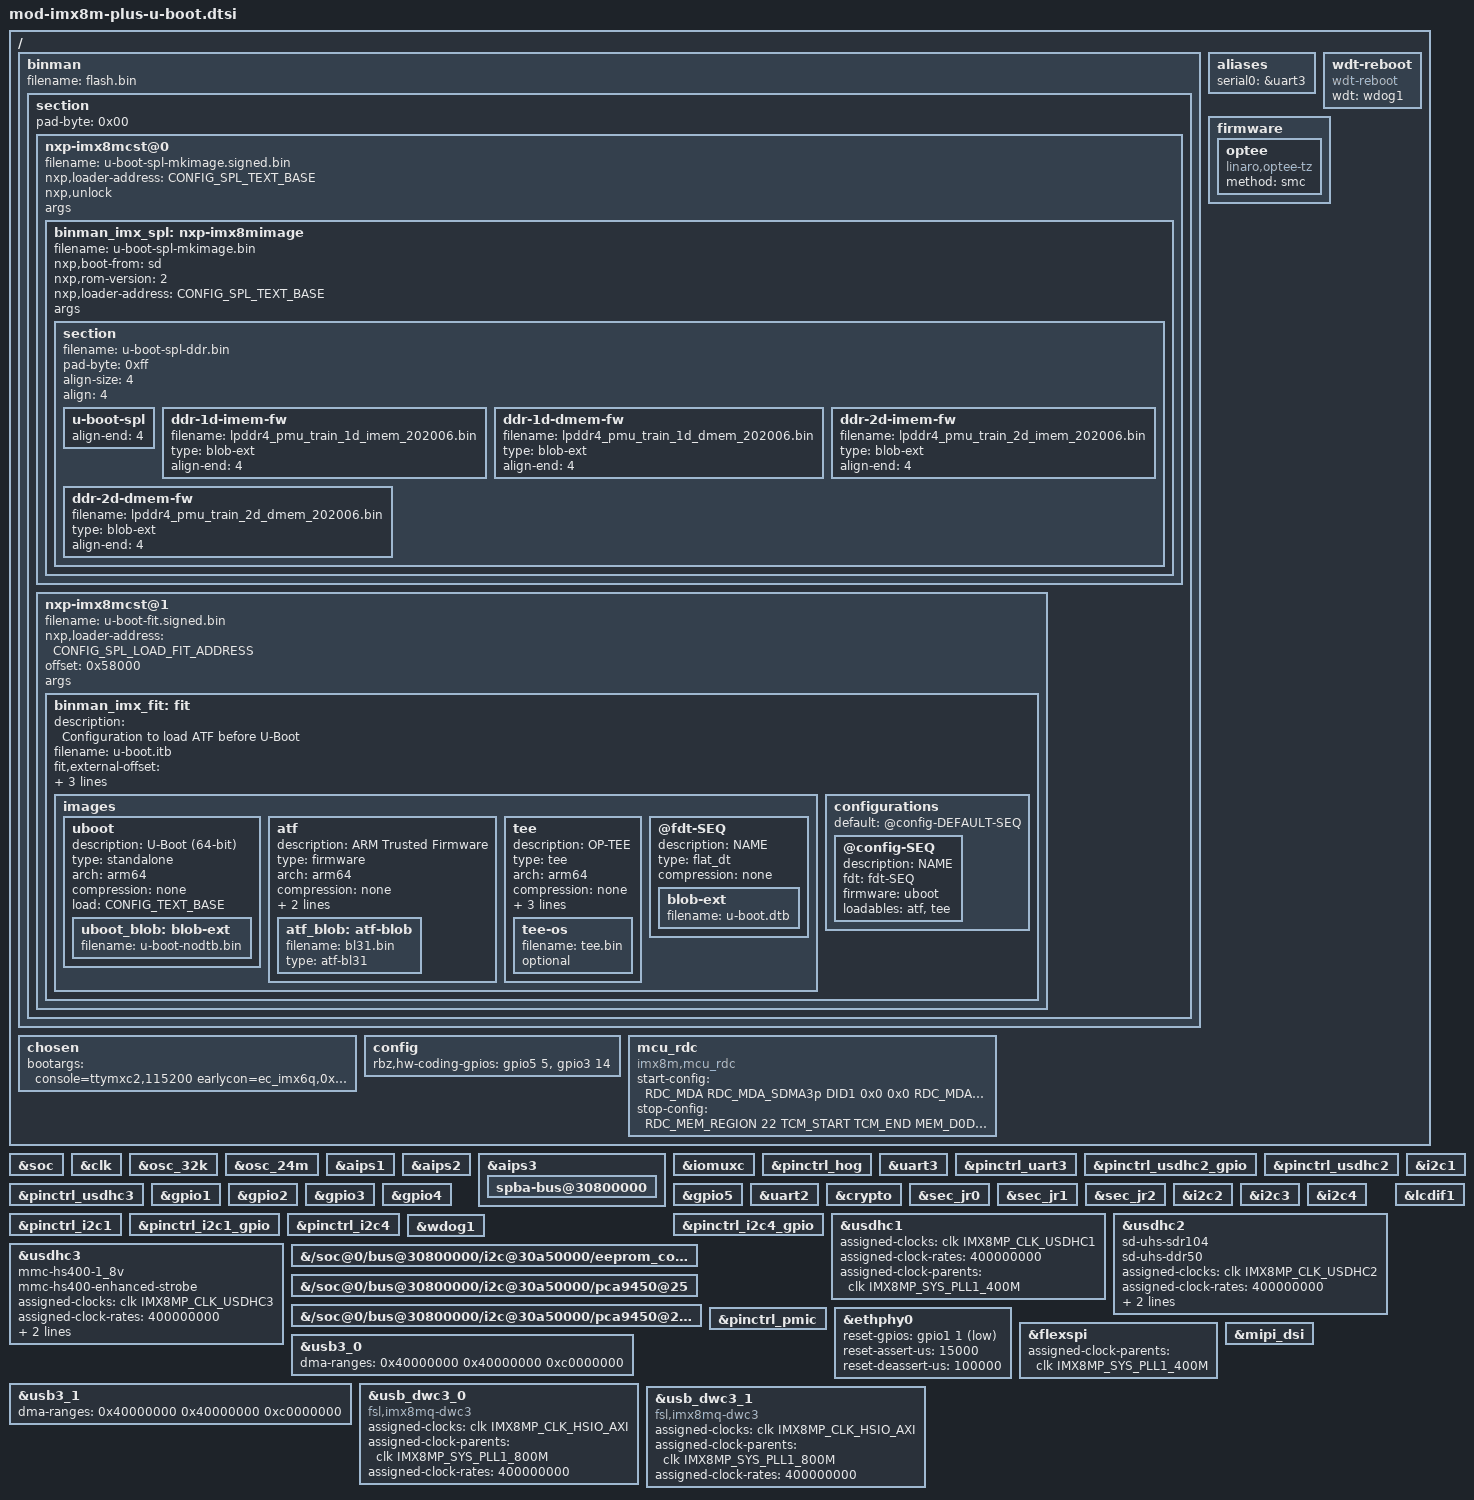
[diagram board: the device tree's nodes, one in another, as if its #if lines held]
// SPDX-License-Identifier: GPL-2.0+
/*
 * Copyright 2019 NXP
 */
#include "imx8mp-sec-def.h"

/ {
	binman: binman {
	};

    aliases {
      serial0 = &uart3;
    };

	chosen {
		bootargs = "console=ttymxc2,115200 earlycon=ec_imx6q,0x30880000,115200";
	};

    config {
      rbz,hw-coding-gpios = <&gpio5 5 0>, <&gpio3 14 0>;
    };

	wdt-reboot {
		compatible = "wdt-reboot";
		wdt = <&wdog1>;
		bootph-pre-ram;
	};

	firmware {
		optee {
			compatible = "linaro,optee-tz";
			method = "smc";
		};
	};

	mcu_rdc {
		compatible = "imx8m,mcu_rdc";
			    /* rdc config when MCU starts
			     * master
			     *   SDMA3p --> domain 1
			     *   SDMA3b --> domian 1
			     *   SDMA3_SPBA2  --> domian 1
			     * peripheral:
			     *   SAI3   --> Only Domian 1 can access
			     *   UART4  --> Only Domian 1 can access
			     *   GPT1   --> Only Domian 1 can access
			     *   SDMA3  --> Only Domian 1 can access
			     * memory:
			     *   TCM    --> Only Domian 1 can access (0x7E0000~0x81FFFF)
			     * end.
			     */
		start-config = <
			    RDC_MDA  RDC_MDA_SDMA3p DID1 0x0 0x0
			    RDC_MDA  RDC_MDA_ENET1_TX DID1 0x0 0x0
			    RDC_MDA  RDC_MDA_ENET1_RX DID1 0x0 0x0
			    RDC_MDA  RDC_MDA_SDMA3b DID1 0x0 0x0
			    RDC_MDA  RDC_MDA_SDMA3_SPBA2 DID1 0x0 0x0
			    RDC_PDAP RDC_PDAP_ENET1 PDAP_D0D1_ACCESS 0x0 0x0
			    RDC_PDAP RDC_PDAP_SAI3  PDAP_D1_ACCESS 0x0 0x0
			    RDC_PDAP RDC_PDAP_UART4 PDAP_D1_ACCESS 0x0 0x0
			    RDC_PDAP RDC_PDAP_GPT1  PDAP_D1_ACCESS 0x0 0x0
			    RDC_PDAP RDC_PDAP_SDMA3 PDAP_D1_ACCESS 0x0 0x0
			    RDC_MEM_REGION 22 TCM_START TCM_END MEM_D1_ACCESS
			    0x0      0x0            0x0  0x0 0x0
			  >;
			    /* rdc config when MCU stops
			     * memory:
			     *   TCM    --> domain 0/1 can access (0x7E0000~0x81FFFF)
			     * end.
			     */
		stop-config = <
			    RDC_MEM_REGION 22 TCM_START TCM_END MEM_D0D1_ACCESS
			    0x0      0x0            0x0  0x0 0x0
			  >;
	};
};

&soc {
	bootph-all;
	bootph-pre-ram;
};

&clk {
	bootph-pre-ram;
	bootph-all;
	/delete-property/ assigned-clocks;
	/delete-property/ assigned-clock-parents;
	/delete-property/ assigned-clock-rates;

};

&osc_32k {
	bootph-pre-ram;
	bootph-all;
};

&osc_24m {
	bootph-pre-ram;
	bootph-all;
};

&aips1 {
	bootph-pre-ram;
	bootph-all;
};

&aips2 {
	bootph-pre-ram;
};

&aips3 {
	bootph-pre-ram;
	spba-bus@30800000 {
		bootph-pre-ram;
	};
};

&iomuxc {
   /* bootph-all;*/
	bootph-pre-ram;
};

&pinctrl_hog {
	bootph-pre-ram;
};

&uart3 {
  bootph-all;
  bootph-pre-ram;
  status = "okay";
};

&pinctrl_uart3 {
    bootph-all;
	bootph-pre-ram;
};

&pinctrl_usdhc2_gpio {
	bootph-pre-ram;
};

&pinctrl_usdhc2 {
	bootph-pre-ram;
};

&pinctrl_usdhc3 {
	bootph-pre-ram;
};

&gpio1 {
	bootph-pre-ram;
};

&gpio2 {
	bootph-pre-ram;
};

&gpio3 {
	bootph-pre-ram;
};

&gpio4 {
	bootph-pre-ram;
};

&gpio5 {
	bootph-pre-ram;
};

&uart2 {
	bootph-pre-ram;
};

&crypto {
	bootph-pre-ram;
};

&sec_jr0 {
	bootph-pre-ram;
};

&sec_jr1 {
	bootph-pre-ram;
};

&sec_jr2 {
	bootph-pre-ram;
};

&i2c1 {
	bootph-pre-ram;
};

&i2c2 {
	bootph-pre-ram;
};

&i2c3 {
	bootph-pre-ram;
};

&i2c4 {
	bootph-pre-ram;
};

&pinctrl_i2c1 {
	bootph-pre-ram;
};

&pinctrl_i2c1_gpio {
	bootph-pre-ram;
};

&pinctrl_i2c4 {
	bootph-pre-ram;
};

&pinctrl_i2c4_gpio {
	bootph-pre-ram;
};

&usdhc1 {
	bootph-pre-ram;
	assigned-clocks = <&clk IMX8MP_CLK_USDHC1>;
	assigned-clock-rates = <400000000>;
	assigned-clock-parents = <&clk IMX8MP_SYS_PLL1_400M>;
};

&usdhc2 {
	bootph-pre-ram;
	sd-uhs-sdr104;
	sd-uhs-ddr50;
	assigned-clocks = <&clk IMX8MP_CLK_USDHC2>;
	assigned-clock-rates = <400000000>;
	assigned-clock-parents = <&clk IMX8MP_SYS_PLL1_400M>;
};

&usdhc3 {
	bootph-pre-ram;
	mmc-hs400-1_8v;
	mmc-hs400-enhanced-strobe;
	assigned-clocks = <&clk IMX8MP_CLK_USDHC3>;
	assigned-clock-rates = <400000000>;
	assigned-clock-parents = <&clk IMX8MP_SYS_PLL1_400M>;
};

&wdog1 {
	bootph-pre-ram;
};

&{/soc@0/bus@30800000/i2c@30a50000/eeprom_config@50} {
	bootph-pre-ram;
};

&{/soc@0/bus@30800000/i2c@30a50000/pca9450@25} {
	bootph-pre-ram;
};

&{/soc@0/bus@30800000/i2c@30a50000/pca9450@25/regulators} {
	bootph-pre-ram;
};

&pinctrl_pmic {
	bootph-pre-ram;
};

&ethphy0 {
	reset-gpios = <&gpio1 1 GPIO_ACTIVE_LOW>;
	reset-assert-us = <15000>;
	reset-deassert-us = <100000>;
}; 

&flexspi {
	assigned-clock-parents = <&clk IMX8MP_SYS_PLL1_400M>;
};

&lcdif1 {
	/delete-property/ assigned-clocks;
	/delete-property/ assigned-clock-parents;
	/delete-property/ assigned-clock-rates;
};

&mipi_dsi {
	/delete-property/ assigned-clocks;
	/delete-property/ assigned-clock-parents;
	/delete-property/ assigned-clock-rates;
};

&usb3_0 {
	dma-ranges = <0x40000000 0x40000000 0xc0000000>;
	/delete-property/ power-domains;
};

&usb3_1 {
	dma-ranges = <0x40000000 0x40000000 0xc0000000>;
	/delete-property/ power-domains;
};

&usb_dwc3_0 {
	compatible = "fsl,imx8mq-dwc3", "snps,dwc3";
	assigned-clocks = <&clk IMX8MP_CLK_HSIO_AXI>;
	assigned-clock-parents = <&clk IMX8MP_SYS_PLL1_800M>;
	assigned-clock-rates = <400000000>;
};

&usb_dwc3_1 {
	compatible = "fsl,imx8mq-dwc3", "snps,dwc3";
	assigned-clocks = <&clk IMX8MP_CLK_HSIO_AXI>;
	assigned-clock-parents = <&clk IMX8MP_SYS_PLL1_800M>;
	assigned-clock-rates = <400000000>;
};

&binman {
	filename = "flash.bin";
	section {
		pad-byte = <0x00>;

#ifdef CONFIG_IMX_HAB
		nxp-imx8mcst@0 {
			filename = "u-boot-spl-mkimage.signed.bin";
			nxp,loader-address = <CONFIG_SPL_TEXT_BASE>;
			nxp,unlock;
			args;	/* Needed by mkimage etype superclass */
#endif

			binman_imx_spl: nxp-imx8mimage {
				filename = "u-boot-spl-mkimage.bin";
				nxp,boot-from = "sd";
				nxp,rom-version = <2>;
				nxp,loader-address = <CONFIG_SPL_TEXT_BASE>;
				args;	/* Needed by mkimage etype superclass */

				section {
					filename = "u-boot-spl-ddr.bin";
					pad-byte = <0xff>;
					align-size = <4>;
					align = <4>;

					u-boot-spl {
						align-end = <4>;
					};

					ddr-1d-imem-fw {
						filename = "lpddr4_pmu_train_1d_imem_202006.bin";
						type = "blob-ext";
						align-end = <4>;
					};

					ddr-1d-dmem-fw {
						filename = "lpddr4_pmu_train_1d_dmem_202006.bin";
						type = "blob-ext";
						align-end = <4>;
					};

					ddr-2d-imem-fw {

						filename = "lpddr4_pmu_train_2d_imem_202006.bin";
						type = "blob-ext";
						align-end = <4>;
					};

					ddr-2d-dmem-fw {
						filename = "lpddr4_pmu_train_2d_dmem_202006.bin";
						type = "blob-ext";
						align-end = <4>;
					};
				};
			};
#ifdef CONFIG_IMX_HAB
		};

		nxp-imx8mcst@1 {
			filename = "u-boot-fit.signed.bin";
			nxp,loader-address = <CONFIG_SPL_LOAD_FIT_ADDRESS>;
			offset = <0x58000>;
			args;	/* Needed by mkimage etype superclass */
#endif

			binman_imx_fit: fit {
				description = "Configuration to load ATF before U-Boot";
				filename = "u-boot.itb";
#ifndef CONFIG_IMX_HAB
				fit,external-offset = <CONFIG_FIT_EXTERNAL_OFFSET>;
#endif
				fit,fdt-list = "of-list";
				#address-cells = <1>;
				offset = <0x58000>;

				images {
					uboot {
						description = "U-Boot (64-bit)";
						type = "standalone";
						arch = "arm64";
						compression = "none";
						load = <CONFIG_TEXT_BASE>;

						uboot_blob: blob-ext {
							filename = "u-boot-nodtb.bin";
						};
					};

#ifndef CONFIG_ARMV8_PSCI
					atf {
						description = "ARM Trusted Firmware";
						type = "firmware";
						arch = "arm64";
						compression = "none";
						load = <0x970000>;
						entry = <0x970000>;

						atf_blob: atf-blob {
							filename = "bl31.bin";
							type = "atf-bl31";
						};
					};
#endif

					tee: tee {
						description = "OP-TEE";
						type = "tee";
						arch = "arm64";
						compression = "none";
						os = "tee";
						load = <CONFIG_IMX8M_OPTEE_LOAD_ADDR>;
						entry = <CONFIG_IMX8M_OPTEE_LOAD_ADDR>;

						tee-os {
							filename = "tee.bin";
                            optional;
						};
					};

					@fdt-SEQ {
						description = "NAME";
						type = "flat_dt";
						compression = "none";

						blob-ext {
							filename = "u-boot.dtb";
						};
					};
				};

				configurations {
					default = "@config-DEFAULT-SEQ";

					@config-SEQ {
						description = "NAME";
						fdt = "fdt-SEQ";
						firmware = "uboot";
#ifndef CONFIG_ARMV8_PSCI
						loadables = "atf", "tee";
#endif
					};
				};
			};
#ifdef CONFIG_IMX_HAB
		};
#endif
	};
};
